# XHSC_HC32L12X register map
Vendor: XHSC Co.Ltd; Series: ARMCM0P; File version: 1.0
CPU: CM0P r0p0, little endian, no MPU, no FPU, 3 interrupt priority bits
Registers are 32-bit, read-write, reset 0x0 unless marked. A register's access mark holds for its fields unless they carry their own. Offsets are from the block's base; [hi:lo] are bit positions; 'fields as' and 'values as' point back to an identical list.

## LVD
Base 0x40002C00
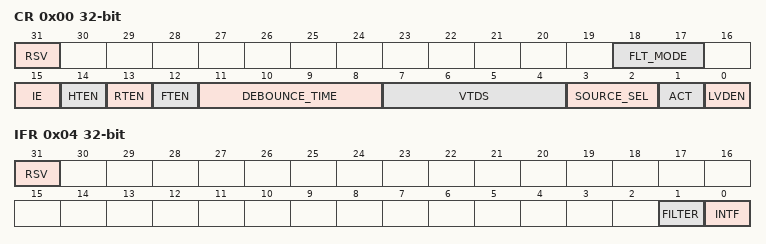
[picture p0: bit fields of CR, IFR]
0x00 CR (reset mask 0xFFFF)
  [31] RSV, [18:17] FLT_MODE, [15] IE, [14] HTEN, [13] RTEN, [12] FTEN, [11:8] DEBOUNCE_TIME, [7:4] VTDS, [3:2] SOURCE_SEL, [1] ACT, [0] LVDEN
0x04 IFR (reset mask 0x3)
  [31] RSV, [1] FILTER ro, [0] INTF

## RAM
Base 0x40020400
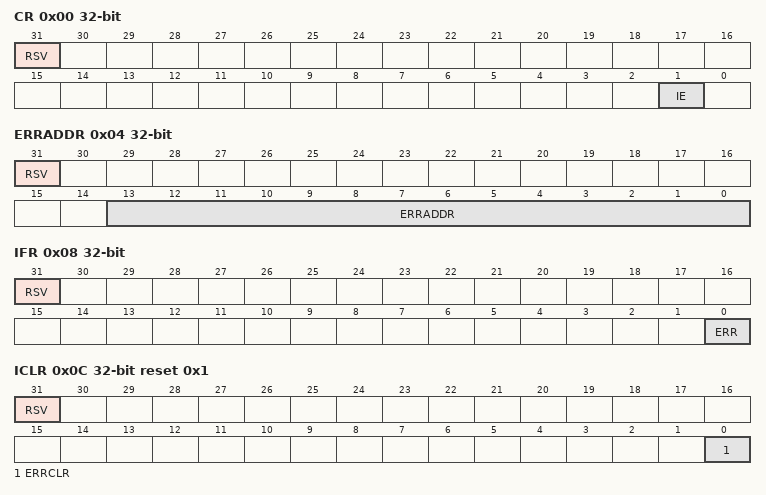
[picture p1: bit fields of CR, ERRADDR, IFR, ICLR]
0x00 CR (reset mask 0x3)
  [31] RSV, [1] IE
0x04 ERRADDR ro (reset mask 0x3FFF)
  [31] RSV rw, [13:0] ERRADDR
0x08 IFR ro (reset mask 0x1)
  [31] RSV, [0] ERR
0x0C ICLR wo reset 0x1 (reset mask 0x1)
  [31] RSV ro, [0] ERRCLR

## RESET
Base 0x4002181C
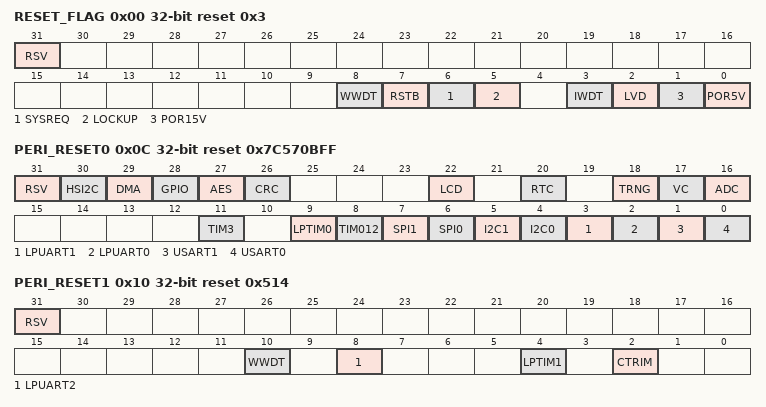
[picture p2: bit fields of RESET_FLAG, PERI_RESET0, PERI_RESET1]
0x00 RESET_FLAG reset 0x3 (reset mask 0x1EF)
  [31] RSV, [8] WWDT, [7] RSTB, [6] SYSREQ, [5] LOCKUP, [3] IWDT, [2] LVD, [1] POR15V, [0] POR5V
0x0C PERI_RESET0 reset 0x7C570BFF (reset mask 0x7C570BFF)
  [31] RSV, [30] HSI2C, [29] DMA, [28] GPIO, [27] AES, [26] CRC, [22] LCD, [20] RTC, [18] TRNG, [17] VC, [16] ADC, [11] TIM3, [9] LPTIM0, [8] TIM012, [7] SPI1, [6] SPI0, [5] I2C1, [4] I2C0, [3] LPUART1, [2] LPUART0, [1] USART1, [0] USART0
0x10 PERI_RESET1 reset 0x514 (reset mask 0x514)
  [31] RSV, [10] WWDT, [8] LPUART2, [4] LPTIM1, [2] CTRIM

## RTC
Base 0x40001400
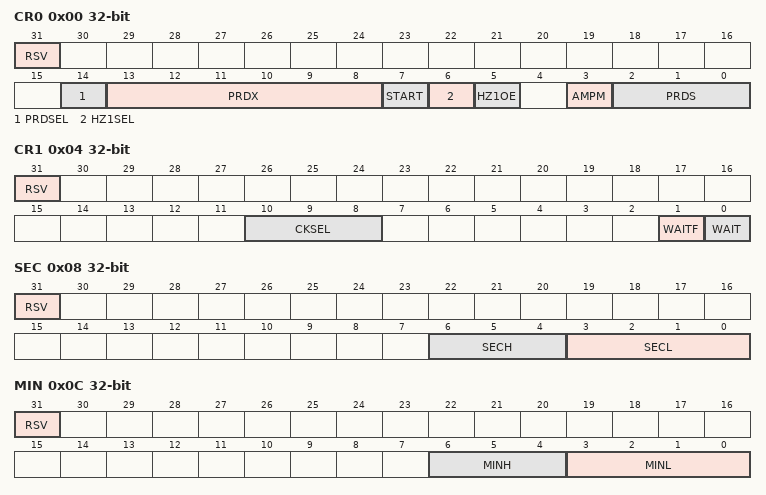
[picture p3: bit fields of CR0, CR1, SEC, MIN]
0x00 CR0 (reset mask 0xFFEF)
  [31] RSV, [14] PRDSEL, [13:8] PRDX, [7] START, [6] HZ1SEL, [5] HZ1OE, [3] AMPM, [2:0] PRDS
0x04 CR1 (reset mask 0x303)
  [31] RSV, [10:8] CKSEL, [1] WAITF, [0] WAIT
0x08 SEC (reset mask 0x7F)
  [31] RSV, [6:4] SECH, [3:0] SECL
0x0C MIN (reset mask 0x7F)
  [31] RSV, [6:4] MINH, [3:0] MINL
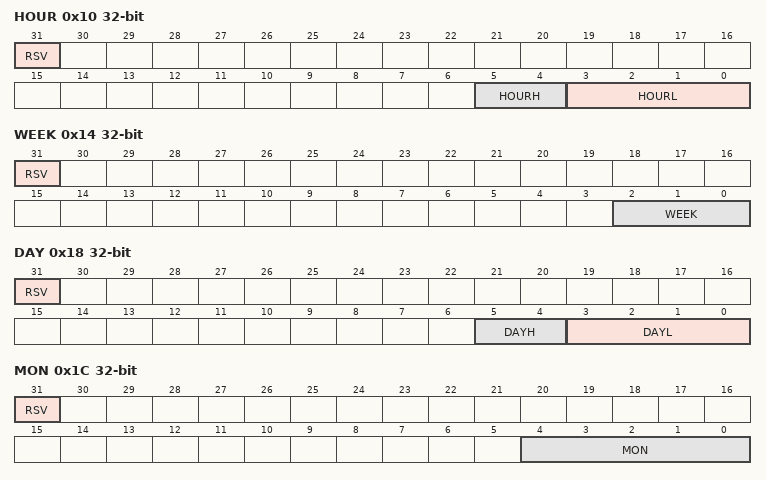
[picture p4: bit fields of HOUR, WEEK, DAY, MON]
0x10 HOUR (reset mask 0x3F)
  [31] RSV, [5:4] HOURH, [3:0] HOURL
0x14 WEEK (reset mask 0x7)
  [31] RSV, [2:0] WEEK
0x18 DAY (reset mask 0x3F)
  [31] RSV, [5:4] DAYH, [3:0] DAYL
0x1C MON (reset mask 0x1F)
  [31] RSV, [4:0] MON
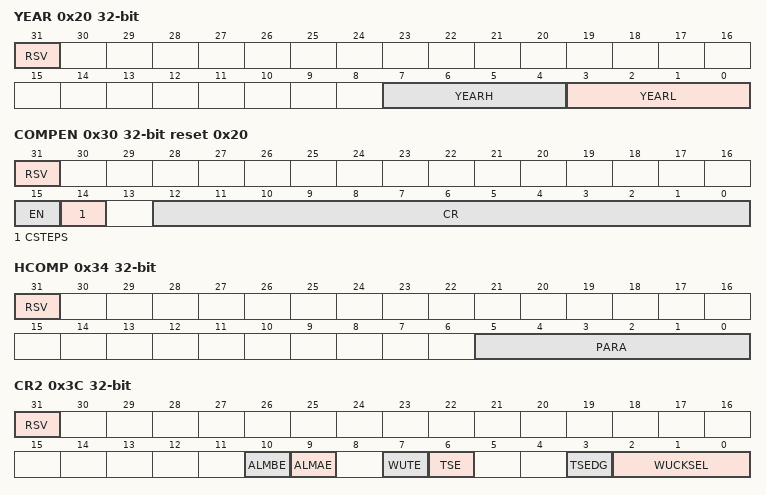
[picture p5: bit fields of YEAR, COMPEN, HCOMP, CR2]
0x20 YEAR (reset mask 0xFF)
  [31] RSV, [7:4] YEARH, [3:0] YEARL
0x30 COMPEN reset 0x20 (reset mask 0x18FF)
  [31] RSV, [15] EN, [14] CSTEPS, [12:0] CR
0x34 HCOMP (reset mask 0x3F)
  [31] RSV, [5:0] PARA
0x3C CR2 (reset mask 0x6FF)
  [31] RSV, [10] ALMBE, [9] ALMAE, [7] WUTE, [6] TSE, [3] TSEDG, [2:0] WUCKSEL
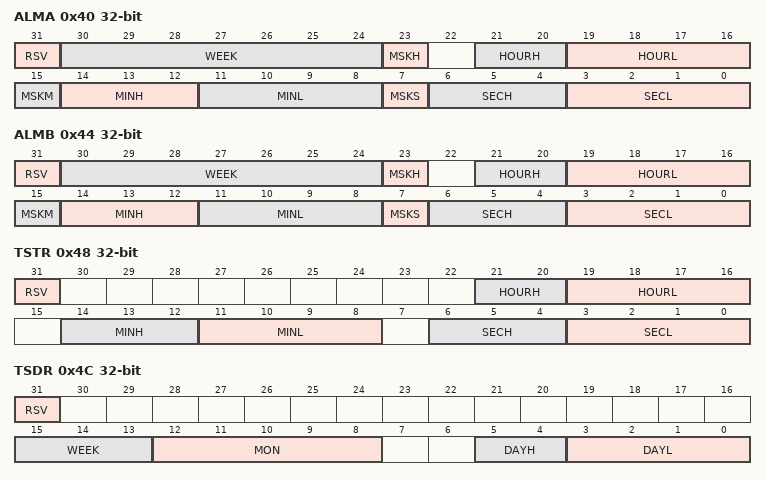
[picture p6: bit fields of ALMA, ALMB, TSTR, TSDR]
0x40 ALMA (reset mask 0x7FBFFFFF)
  [31] RSV, [30:24] WEEK, [23] MSKH, [21:20] HOURH, [19:16] HOURL, [15] MSKM, [14:12] MINH, [11:8] MINL, [7] MSKS, [6:4] SECH, [3:0] SECL
0x44 ALMB (reset mask 0x7FBFFFFF)
  fields as ALMA
0x48 TSTR ro (reset mask 0x3F7F7F)
  [31] RSV, [21:20] HOURH, [19:16] HOURL, [14:12] MINH, [11:8] MINL, [6:4] SECH, [3:0] SECL
0x4C TSDR ro (reset mask 0xFF3F)
  [31] RSV, [15:13] WEEK, [12:8] MON, [5:4] DAYH, [3:0] DAYL
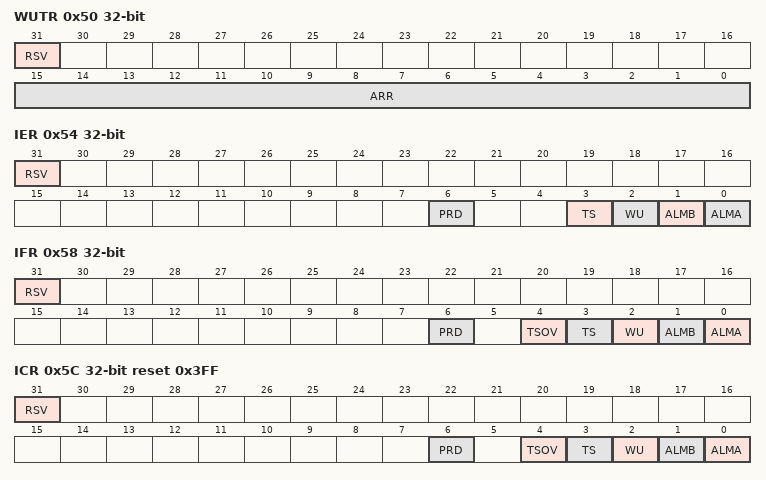
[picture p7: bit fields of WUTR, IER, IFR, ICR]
0x50 WUTR (reset mask 0xFFFF)
  [31] RSV, [15:0] ARR
0x54 IER (reset mask 0x5F)
  [31] RSV, [6] PRD, [3] TS, [2] WU, [1] ALMB, [0] ALMA
0x58 IFR ro (reset mask 0x5F)
  [31] RSV, [6] PRD, [4] TSOV, [3] TS, [2] WU, [1] ALMB, [0] ALMA
0x5C ICR reset 0x3FF (reset mask 0x5F)
  [31] RSV, [6] PRD wo, [4] TSOV wo, [3] TS wo, [2] WU wo, [1] ALMB wo, [0] ALMA wo
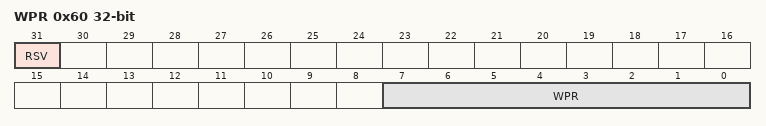
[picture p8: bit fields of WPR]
0x60 WPR (reset mask 0xFF)
  [31] RSV, [7:0] WPR

## SPI0 — desc SPI
Base 0x40000800
Same registers: SPI1 0x40008800
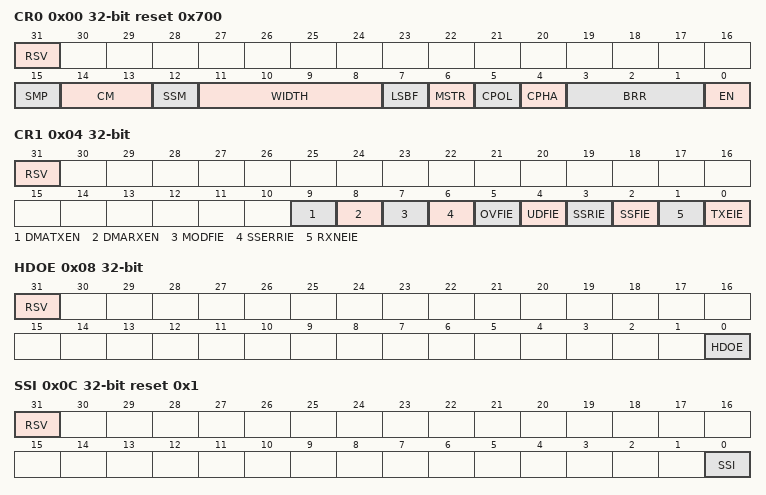
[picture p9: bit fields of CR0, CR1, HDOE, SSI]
0x00 CR0 reset 0x700 (reset mask 0xFFFF)
  [31] RSV, [15] SMP, [14:13] CM, [12] SSM, [11:8] WIDTH, [7] LSBF, [6] MSTR, [5] CPOL, [4] CPHA, [3:1] BRR, [0] EN
0x04 CR1 (reset mask 0x3FF)
  [31] RSV, [9] DMATXEN, [8] DMARXEN, [7] MODFIE, [6] SSERRIE, [5] OVFIE, [4] UDFIE, [3] SSRIE, [2] SSFIE, [1] RXNEIE, [0] TXEIE
0x08 HDOE (reset mask 0x1)
  [31] RSV, [0] HDOE
0x0C SSI reset 0x1 (reset mask 0x1)
  [31] RSV, [0] SSI
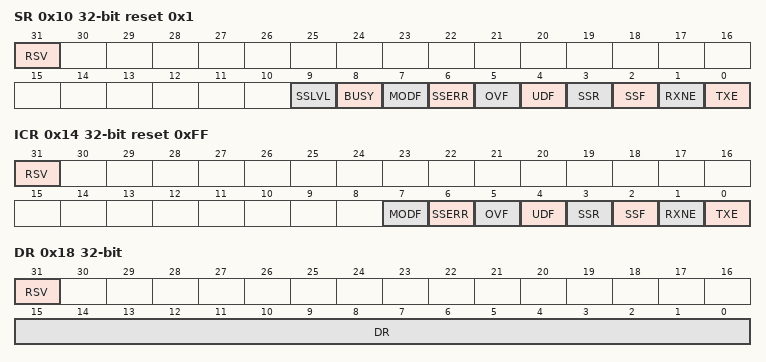
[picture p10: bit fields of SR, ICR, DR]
0x10 SR ro reset 0x1 (reset mask 0x3FF)
  [31] RSV, [9] SSLVL, [8] BUSY, [7] MODF, [6] SSERR, [5] OVF, [4] UDF, [3] SSR, [2] SSF, [1] RXNE, [0] TXE
0x14 ICR wo reset 0xFF (reset mask 0xBE)
  [31] RSV, [7] MODF, [6] SSERR, [5] OVF, [4] UDF, [3] SSR, [2] SSF, [1] RXNE, [0] TXE
0x18 DR (reset mask 0xFF)
  [31] RSV, [15:0] DR
